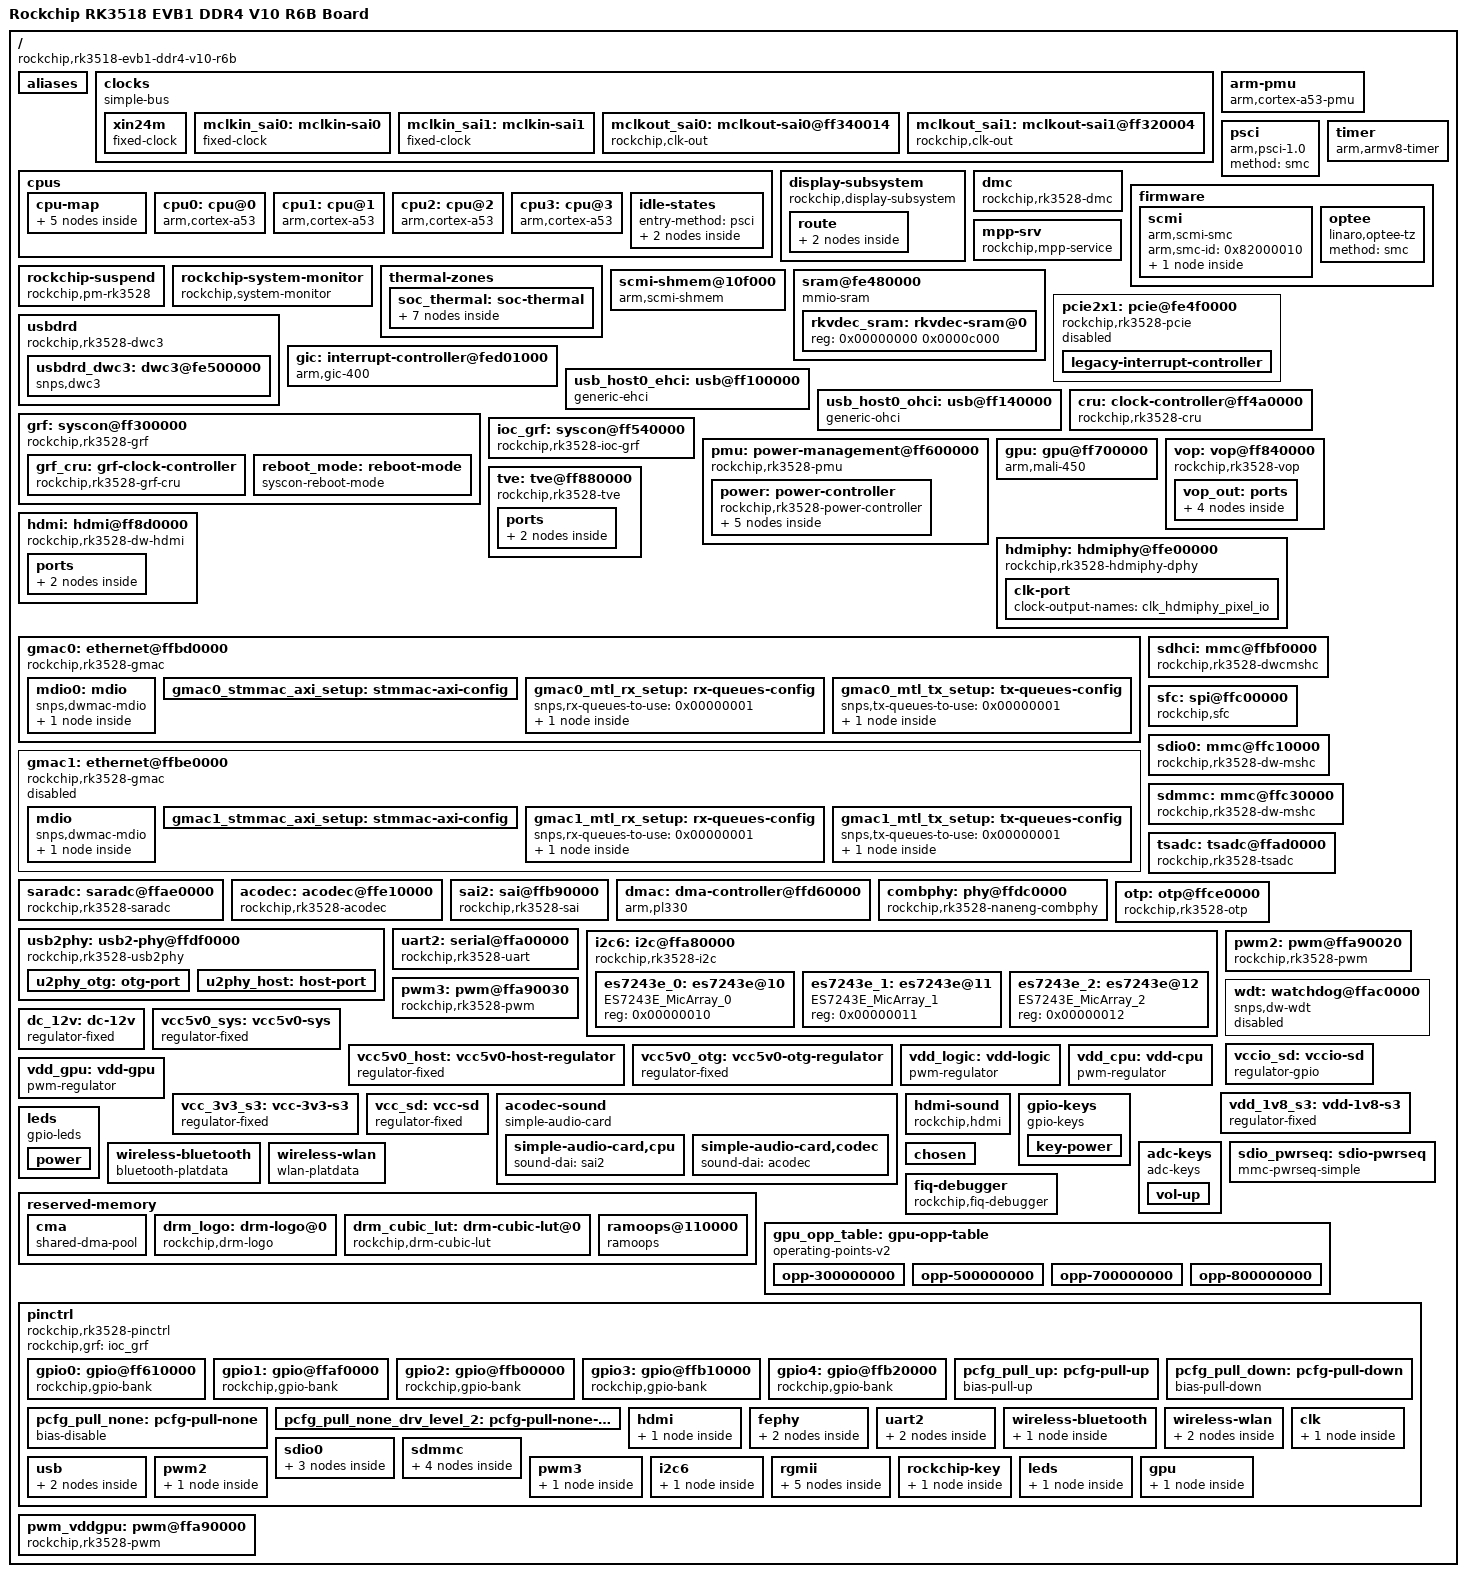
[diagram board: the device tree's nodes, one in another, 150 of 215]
/dts-v1/;

/ {
	compatible = "rockchip,rk3518-evb1-ddr4-v10-r6b", "rockchip,rk3528";
	model = "Rockchip RK3518 EVB1 DDR4 V10 R6B Board";
	interrupt-parent = <0x00000001>;
	#address-cells = <0x00000002>;
	#size-cells = <0x00000002>;

	aliases {
		ethernet0 = "/ethernet@ffbd0000";
		ethernet1 = "/ethernet@ffbe0000";
		gpio0 = "/pinctrl/gpio@ff610000";
		gpio1 = "/pinctrl/gpio@ffaf0000";
		gpio2 = "/pinctrl/gpio@ffb00000";
		gpio3 = "/pinctrl/gpio@ffb10000";
		gpio4 = "/pinctrl/gpio@ffb20000";
		i2c0 = "/i2c@ffa50000";
		i2c1 = "/i2c@ffa58000";
		i2c2 = "/i2c@ffa60000";
		i2c3 = "/i2c@ffa68000";
		i2c4 = "/i2c@ffa70000";
		i2c5 = "/i2c@ffa78000";
		i2c6 = "/i2c@ffa80000";
		i2c7 = "/i2c@ffa88000";
		serial0 = "/serial@ff9f0000";
		serial1 = "/serial@ff9f8000";
		serial2 = "/serial@ffa00000";
		serial3 = "/serial@ffa08000";
		serial4 = "/serial@ffa10000";
		serial5 = "/serial@ffa18000";
		serial6 = "/serial@ffa20000";
		serial7 = "/serial@ffa28000";
		spi0 = "/spi@ff9c0000";
		spi1 = "/spi@ff9d0000";
		spi2 = "/spi@ffc00000";
	};

	clocks {
		compatible = "simple-bus";
		#address-cells = <0x00000002>;
		#size-cells = <0x00000002>;
		ranges;

		xin24m: xin24m {
			compatible = "fixed-clock";
			#clock-cells = <0x00000000>;
			clock-frequency = <0x016e3600>;
			clock-output-names = "xin24m";
		};

		mclkin_sai0: mclkin-sai0 {
			compatible = "fixed-clock";
			#clock-cells = <0x00000000>;
			clock-frequency = <0x00000000>;
			clock-output-names = "i2s0_mclkin";
		};

		mclkin_sai1: mclkin-sai1 {
			compatible = "fixed-clock";
			#clock-cells = <0x00000000>;
			clock-frequency = <0x00000000>;
			clock-output-names = "i2s1_mclkin";
		};

		mclkout_sai0: mclkout-sai0@ff340014 {
			compatible = "rockchip,clk-out";
			reg = <0x00000000 0xff340014 0x00000000 0x00000004>;
			#clock-cells = <0x00000000>;
			clock-output-names = "mclk_sai0_to_io";
			rockchip,bit-shift = <0x00000001>;
			rockchip,bit-set-to-disable;
		};

		mclkout_sai1: mclkout-sai1@ff320004 {
			compatible = "rockchip,clk-out";
			reg = <0x00000000 0xff320004 0x00000000 0x00000004>;
			#clock-cells = <0x00000000>;
			clock-output-names = "mclk_sai1_to_io";
			rockchip,bit-shift = <0x0000000e>;
			rockchip,bit-set-to-disable;
		};
	};

	cpus {
		#address-cells = <0x00000002>;
		#size-cells = <0x00000000>;

		cpu-map {
			cluster0 {
				core0 { cpu = <&cpu0>; };
				core1 { cpu = <&cpu1>; };
				core2 { cpu = <&cpu2>; };
				core3 { cpu = <&cpu3>; };
			};
		};

		cpu0: cpu@0 {
			device_type = "cpu";
			compatible = "arm,cortex-a53";
			reg = <0x00000000 0x00000000>;
			enable-method = "psci";
			#cooling-cells = <0x00000002>;
			dynamic-power-coefficient = <0x00000093>;
			cpu-idle-states = <&CPU_SLEEP>;
		};

		cpu1: cpu@1 {
			device_type = "cpu";
			compatible = "arm,cortex-a53";
			reg = <0x00000000 0x00000001>;
			enable-method = "psci";
			cpu-idle-states = <&CPU_SLEEP>;
		};

		cpu2: cpu@2 {
			device_type = "cpu";
			compatible = "arm,cortex-a53";
			reg = <0x00000000 0x00000002>;
			enable-method = "psci";
			cpu-idle-states = <&CPU_SLEEP>;
		};

		cpu3: cpu@3 {
			device_type = "cpu";
			compatible = "arm,cortex-a53";
			reg = <0x00000000 0x00000003>;
			enable-method = "psci";
			cpu-idle-states = <&CPU_SLEEP>;
		};

		idle-states {
			entry-method = "psci";

			cpu-sleep0 {
				compatible = "arm,idle-state";
				local-timer-stop;
				arm,psci-suspend-param = <0x00010000>;
				entry-latency-us = <0x00000078>;
				exit-latency-us = <0x000000fa>;
				min-residency-us = <0x00000384>;
				status = "disabled";
			};

			CPU_SLEEP: cpu-sleep {
				compatible = "arm,idle-state";
				local-timer-stop;
				arm,psci-suspend-param = <0x00010000>;
				entry-latency-us = <0x00000078>;
				exit-latency-us = <0x000000fa>;
				min-residency-us = <0x00000384>;
				status = "okay";
			};
		};
	};

	arm-pmu {
		compatible = "arm,cortex-a53-pmu";
		interrupts = <0x00000000 0x000000ab 0x00000004
		              0x00000000 0x000000ac 0x00000004
		              0x00000000 0x000000ad 0x00000004
		              0x00000000 0x000000ae 0x00000004>;
		interrupt-affinity = <&cpu0>, <&cpu1>, <&cpu2>, <&cpu3>;
	};

	psci {
		compatible = "arm,psci-1.0";
		method = "smc";
	};

	timer {
		compatible = "arm,armv8-timer";
		interrupts = <0x00000001 0x0000000d 0x00000f08
		              0x00000001 0x0000000e 0x00000f08
		              0x00000001 0x0000000b 0x00000f08
		              0x00000001 0x0000000a 0x00000f08>;
	};

	display-subsystem {
		compatible = "rockchip,display-subsystem";
		ports = <&vop_out>;
		status = "okay";
		memory-region = <&drm_logo>, <&drm_cubic_lut>;
		memory-region-names = "drm-logo", "drm-cubic-lut";

		route {
			route-hdmi {
				status = "okay";
				logo,uboot = "logo.bmp";
				logo,kernel = "logo_kernel.bmp";
				logo,mode = "fullscreen";
				charge_logo,mode = "fullscreen";
				connect = <&vp0_out_hdmi>;
			};

			route-tve {
				status = "okay";
				logo,uboot = "logo.bmp";
				logo,kernel = "logo_kernel.bmp";
				logo,mode = "fullscreen";
				charge_logo,mode = "fullscreen";
				connect = <&vp1_out_tve>;
			};
		};
	};

	dmc: dmc {
		compatible = "rockchip,rk3528-dmc";
		interrupts = <0x00000000 0x00000011 0x00000004>;
		interrupt-names = "complete";
		devfreq = <&dmc>;
		clocks = <&scmi_clk 0x00000014>;
		clock-names = "dmc_clk";
		upthreshold = <0x00000028>;
		system-status-level = <0x00000001 0x00000008>;
		auto-min-freq = <0x0004f1a0>;
		auto-freq-en = <0x00000000>;
		status = "okay";
		center-supply = <&vdd_logic>;
	};

	firmware {
		scmi: scmi {
			compatible = "arm,scmi-smc";
			arm,smc-id = <0x82000010>;
			#address-cells = <0x00000001>;
			#size-cells = <0x00000000>;

			scmi_clk: protocol@14 {
				reg = <0x00000014>;
				#clock-cells = <0x00000001>;
				assigned-clocks = <&scmi_clk 0x00000015>;
				assigned-clock-rates = <0x47868c00>;
			};
		};

		optee {
			compatible = "linaro,optee-tz";
			method = "smc";
		};
	};

	mpp-srv {
		compatible = "rockchip,mpp-service";
		rockchip,taskqueue-count = <0x00000005>;
		rockchip,resetgroup-count = <0x00000005>;
		rockchip,iommu-shared-mask = <0x0000420a>;
		status = "okay";
	};

	rockchip-suspend {
		compatible = "rockchip,pm-rk3528";
		status = "okay";
		rockchip,sleep-debug-en = <0x00000001>;
		rockchip,sleep-mode-config = <0x00000001>;
		rockchip,wakeup-config = <0x00000011>;
		rockchip,pwm-regulator-config = <0x00000003>;
	};

	rockchip-system-monitor {
		compatible = "rockchip,system-monitor";
		rockchip,thermal-zone = "soc-thermal";
		rockchip,polling-delay = <0x000000c8>;
		rockchip,temp-hysteresis = <0x00001388>;
		rockchip,offline-cpu-temp = <0x00019a28>;
		rockchip,temp-offline-cpus = "2-3";
	};

	thermal-zones {
		soc_thermal: soc-thermal {
			polling-delay-passive = <0x00000014>;
			polling-delay = <0x000003e8>;
			sustainable-power = <0x0000027e>;
			thermal-sensors = <&tsadc 0x00000000>;

			trips {
				threshold: trip-point-0 {
					temperature = <0x00017318>;
					hysteresis = <0x000007d0>;
					type = "passive";
				};

				target: trip-point-1 {
					temperature = <0x0001adb0>;
					hysteresis = <0x000007d0>;
					type = "passive";
				};

				soc_crit: soc-crit {
					temperature = <0x0001d4c0>;
					hysteresis = <0x000007d0>;
					type = "critical";
				};
			};

			cooling-maps {
				map0 {
					trip = <&target>;
					cooling-device = <&cpu0 0xffffffff 0xffffffff>;
					contribution = <0x00000400>;
				};

				map1 {
					trip = <&target>;
					cooling-device = <&gpu 0xffffffff 0xffffffff>;
					contribution = <0x00000400>;
				};
			};
		};
	};

	scmi-shmem@10f000 {
		compatible = "arm,scmi-shmem";
		reg = <0x00000000 0x0010f000 0x00000000 0x00000100>;
	};

	sram@fe480000 {
		compatible = "mmio-sram";
		reg = <0x00000000 0xfe480000 0x00000000 0x0000c000>;
		#address-cells = <0x00000001>;
		#size-cells = <0x00000001>;
		ranges = <0x00000000 0x00000000 0xfe480000 0x0000c000>;

		rkvdec_sram: rkvdec-sram@0 {
			reg = <0x00000000 0x0000c000>;
		};
	};

	pcie2x1: pcie@fe4f0000 {
		compatible = "rockchip,rk3528-pcie", "snps,dw-pcie";
		#address-cells = <0x00000003>;
		#size-cells = <0x00000002>;
		bus-range = <0x00000000 0x000000ff>;
		device_type = "pci";
		max-link-speed = <0x00000002>;
		num-lanes = <0x00000001>;
		num-ib-windows = <0x00000008>;
		num-ob-windows = <0x00000008>;
		num-viewport = <0x00000004>;
		linux,pci-domain = <0x00000000>;
		reg = <0x00000000 0xfe4f0000 0x00000000 0x00010000
		       0x00000000 0xfe000000 0x00000000 0x00400000
		       0x00000000 0xfc000000 0x00000000 0x00100000>;
		reg-names = "pcie-apb", "pcie-dbi", "config";
		resets = <&cru 0x000001e3>, <&cru 0x000001e1>, <&cru 0x0000019b>;
		reset-names = "aclk", "pclk", "preset_cru";
		status = "disabled";

		legacy-interrupt-controller {
			interrupt-controller;
			#address-cells = <0x00000000>;
			#interrupt-cells = <0x00000001>;
			interrupts = <0x00000000 0x00000071 0x00000004>;
		};
	};

	usbdrd: usbdrd {
		compatible = "rockchip,rk3528-dwc3", "rockchip,rk3399-dwc3";
		clocks = <&cru 0x00000106>, <&cru 0x00000107>, <&cru 0x00000105>;
		clock-names = "ref_clk", "suspend_clk", "bus_clk";
		#address-cells = <0x00000002>;
		#size-cells = <0x00000002>;
		ranges;
		status = "okay";

		usbdrd_dwc3: dwc3@fe500000 {
			compatible = "snps,dwc3";
			reg = <0x00000000 0xfe500000 0x00000000 0x00400000>;
			interrupts = <0x00000000 0x00000098 0x00000004>;
			dr_mode = "host";
			phys = <&u2phy_otg>, <&combphy 0x00000004>;
			phy-names = "usb2-phy", "usb3-phy";
			phy_type = "utmi_wide";
			resets = <&cru 0x00000211>;
			reset-names = "usb3-otg";
			snps,dis_enblslpm_quirk;
			snps,dis-u1-entry-quirk;
			snps,dis-u2-entry-quirk;
			snps,dis-u2-freeclk-exists-quirk;
			snps,dis-del-phy-power-chg-quirk;
			snps,dis-tx-ipgap-linecheck-quirk;
			snps,dis_rxdet_inp3_quirk;
			snps,parkmode-disable-hs-quirk;
			snps,parkmode-disable-ss-quirk;
			quirk-skip-phy-init;
			status = "okay";
		};
	};

	gic: interrupt-controller@fed01000 {
		compatible = "arm,gic-400";
		#interrupt-cells = <0x00000003>;
		#address-cells = <0x00000000>;
		interrupt-controller;
		reg = <0x00000000 0xfed01000 0x00000000 0x00001000
		       0x00000000 0xfed02000 0x00000000 0x00002000
		       0x00000000 0xfed04000 0x00000000 0x00002000
		       0x00000000 0xfed06000 0x00000000 0x00002000>;
		interrupts = <0x00000001 0x00000009 0x00000f08>;
	};

	usb_host0_ehci: usb@ff100000 {
		compatible = "generic-ehci";
		reg = <0x00000000 0xff100000 0x00000000 0x00040000>;
		interrupts = <0x00000000 0x0000008f 0x00000004>;
		clocks = <&cru 0x000001a0>, <&cru 0x000001a1>, <&u2phy_host>;
		clock-names = "usbhost", "arbiter", "utmi";
		phys = <&u2phy_host>;
		phy-names = "usb2-phy";
		status = "okay";
	};

	usb_host0_ohci: usb@ff140000 {
		compatible = "generic-ohci";
		reg = <0x00000000 0xff140000 0x00000000 0x00040000>;
		interrupts = <0x00000000 0x00000090 0x00000004>;
		clocks = <&cru 0x000001a0>, <&cru 0x000001a1>, <&u2phy_host>;
		clock-names = "usbhost", "arbiter", "utmi";
		phys = <&u2phy_host>;
		phy-names = "usb2-phy";
		status = "okay";
	};

	grf: syscon@ff300000 {
		compatible = "rockchip,rk3528-grf", "syscon", "simple-mfd";
		reg = <0x00000000 0xff300000 0x00000000 0x00090000>;

		grf_cru: grf-clock-controller {
			compatible = "rockchip,rk3528-grf-cru";
			#clock-cells = <0x00000001>;
		};

		reboot_mode: reboot-mode {
			compatible = "syscon-reboot-mode";
			offset = <0x00000200>;
			mode-bootloader = <0x5242c309>;
			mode-charge = <0x5242c30b>;
			mode-fastboot = <0x5242c303>;
			mode-normal = <0x5242c301>;
			mode-recovery = <0x5242c30f>;
			mode-ums = <0x5242c30c>;
			mode-panic = <0x5242c307>;
			mode-watchdog = <0x5242c308>;
		};
	};

	cru: clock-controller@ff4a0000 {
		compatible = "rockchip,rk3528-cru";
		reg = <0x00000000 0xff4a0000 0x00000000 0x00030000>;
		rockchip,grf = <&grf>;
		#clock-cells = <0x00000001>;
		#reset-cells = <0x00000001>;
		assigned-clocks = <&scmi_clk 0x00000015>;
		assigned-clock-rates = <0x47868c00>;
	};

	ioc_grf: syscon@ff540000 {
		compatible = "rockchip,rk3528-ioc-grf", "syscon";
		reg = <0x00000000 0xff540000 0x00000000 0x00040000>;
	};

	pmu: power-management@ff600000 {
		compatible = "rockchip,rk3528-pmu", "simple-mfd";
		reg = <0x00000000 0xff600000 0x00000000 0x00002000>;

		power: power-controller {
			compatible = "rockchip,rk3528-power-controller";
			#power-domain-cells = <0x00000001>;
			#address-cells = <0x00000001>;
			#size-cells = <0x00000000>;
			status = "okay";

			pd_gpu: pd_gpu@4 {
				reg = <0x00000004>;
			};

			pd_rkvdec: pd_rkvdec@5 {
				reg = <0x00000005>;
			};

			pd_rkvenc: pd_rkvenc@6 {
				reg = <0x00000006>;
			};

			pd_vo: pd_vo@7 {
				reg = <0x00000007>;
			};

			pd_vpu: pd_vpu@8 {
				reg = <0x00000008>;
			};
		};
	};

	gpu: gpu@ff700000 {
		compatible = "arm,mali-450";
		reg = <0x00000000 0xff700000 0x00000000 0x00040000>;
		clocks = <&scmi_clk 0x00000016>, <&cru 0x00000113>, <&cru 0x0000010e>;
		clock-names = "clk_mali", "aclk_gpu_mali", "pclk_gpu";
		assigned-clocks = <&scmi_clk 0x00000016>;
		assigned-clock-rates = <0x11e1a300>;
		power-domains = <&power 0x00000004>;
		operating-points-v2 = <&gpu_opp_table>;
		#cooling-cells = <0x00000002>;
		rockchip,grf = <&grf>;
		status = "okay";
		mali-supply = <&vdd_gpu>;
	};

	vop: vop@ff840000 {
		compatible = "rockchip,rk3528-vop";
		reg = <0x00000000 0xff840000 0x00000000 0x00003000
		       0x00000000 0xff845000 0x00000000 0x00001000
		       0x00000000 0xff846400 0x00000000 0x00000800>;
		reg-names = "regs", "gamma_lut", "acm_regs";
		interrupts = <0x00000000 0x0000006d 0x00000004>;
		clocks = <&cru 0x00000157>, <&cru 0x00000154>,
		         <&cru 0x00000155>, <&cru 0x00000156>;
		clock-names = "aclk_vop", "hclk_vop", "dclk_vp0", "dclk_vp1";
		assigned-clocks = <&cru 0x00000155>;
		rockchip,grf = <&grf>;
		status = "okay";

		vop_out: ports {
			#address-cells = <0x00000001>;

			port@0 {
				reg = <0x00000000>;
				#address-cells = <0x00000001>;
				#size-cells = <0x00000000>;

				vp0_out_hdmi: endpoint@0 {
					reg = <0x00000000>;
					remote-endpoint = <&hdmi_in_vp0>;
				};
			};

			port@1 {
				reg = <0x00000001>;
				#address-cells = <0x00000001>;
				#size-cells = <0x00000000>;

				vp1_out_tve: endpoint@0 {
					reg = <0x00000000>;
					remote-endpoint = <&tve_in_vp1>;
				};
			};
		};
	};

	tve: tve@ff880000 {
		compatible = "rockchip,rk3528-tve";
		reg = <0x00000000 0xff880000 0x00000000 0x00004000
		       0x00000000 0xffe00000 0x00000000 0x00000300>;
		interrupts = <0x00000000 0x00000068 0x00000004>;
		clocks = <&cru 0x00000166>, <&cru 0x0000018f>,
		         <&cru 0x00000167>, <&cru 0x00000168>;
		clock-names = "hclk", "pclk_vdac", "dclk", "dclk_4x";
		rockchip,grf = <&grf>;
		status = "okay";

		ports {
			#address-cells = <0x00000001>;
			#size-cells = <0x00000000>;

			port@0 {
				reg = <0x00000000>;
				#address-cells = <0x00000001>;
				#size-cells = <0x00000000>;

				tve_in_vp1: endpoint@0 {
					reg = <0x00000000>;
					remote-endpoint = <&vp1_out_tve>;
					status = "okay";
				};
			};
		};
	};

	hdmi: hdmi@ff8d0000 {
		compatible = "rockchip,rk3528-dw-hdmi";
		reg = <0x00000000 0xff8d0000 0x00000000 0x00020000
		       0x00000000 0xff610000 0x00000000 0x00000200>;
		interrupts = <0x00000000 0x00000066 0x00000004
		              0x00000000 0x00000067 0x00000004>;
		interrupt-names = "hdmi", "hdmi_wakeup";
		clocks = <&cru 0x00000158>, <&cru 0x00000159>,
		         <&cru 0x0000015a>, <&cru 0x00000155>;
		clock-names = "iahb", "isfr", "cec", "dclk_vp0";
		ddc-i2c-scl-high-time-ns = <0x00002599>;
		ddc-i2c-scl-low-time-ns = <0x00002710>;
		reg-io-width = <0x00000004>;
		rockchip,grf = <&grf>;
		rockchip,cts-manual;
		pinctrl-names = "default";
		pinctrl-0 = <&hdmi_pins>;
		phys = <&hdmiphy>;
		phy-names = "hdmi";
		#sound-dai-cells = <0x00000000>;
		hpd-gpios = <&gpio0 0x00000002 0x00000000>;
		status = "okay";

		ports {
			#address-cells = <0x00000001>;
			#size-cells = <0x00000000>;

			port@0 {
				reg = <0x00000000>;
				#address-cells = <0x00000001>;
				#size-cells = <0x00000000>;

				hdmi_in_vp0: endpoint@0 {
					reg = <0x00000000>;
					remote-endpoint = <&vp0_out_hdmi>;
					status = "okay";
				};
			};
		};
	};

	hdmiphy: hdmiphy@ffe00000 {
		compatible = "rockchip,rk3528-hdmiphy-dphy";
		reg = <0x00000000 0xffe00000 0x00000000 0x00010000>;
		interrupts = <0x00000000 0x00000065 0x00000004>;
		#phy-cells = <0x00000000>;
		clocks = <&cru 0x00000160>, <&xin24m>;
		clock-names = "sysclk", "refclk";
		status = "okay";

		clk-port {
			#clock-cells = <0x00000000>;
			clock-output-names = "clk_hdmiphy_pixel_io";
			status = "okay";
		};
	};

	gmac0: ethernet@ffbd0000 {
		compatible = "rockchip,rk3528-gmac", "snps,dwmac-4.20a";
		reg = <0x00000000 0xffbd0000 0x00000000 0x00010000>;
		interrupts = <0x00000000 0x00000071 0x00000004
		              0x00000000 0x00000074 0x00000004>;
		interrupt-names = "macirq", "eth_wake_irq";
		rockchip,grf = <&grf>;
		clocks = <&cru 0x0000017b>, <&cru 0x0000017e>, <&cru 0x0000017d>,
		         <&cru 0x0000017a>, <&cru 0x00000179>;
		clock-names = "stmmaceth", "clk_mac_ref", "mac_clk_rx",
		              "mac_clk_tx", "pclk_mac", "aclk_mac";
		resets = <&cru 0x0000029a>;
		reset-names = "stmmaceth";
		snps,mixed-burst;
		snps,axi-config = <&gmac0_stmmac_axi_setup>;
		snps,mtl-rx-config = <&gmac0_mtl_rx_setup>;
		snps,mtl-tx-config = <&gmac0_mtl_tx_setup>;
		phy-mode = "rmii";
		clock_in_out = "input";
		phy-handle = <&rmii0_phy>;
		status = "okay";

		mdio0: mdio {
			compatible = "snps,dwmac-mdio";
			#address-cells = <0x00000001>;
			#size-cells = <0x00000000>;

			rmii0_phy: ethernet-phy@2 {
				compatible = "ethernet-phy-id0044.1400", "ethernet-phy-ieee802.3-c22";
				reg = <0x00000002>;
				clocks = <&cru 0x0000018e>;
				resets = <&cru 0x000002a3>;
				phy-is-integrated;
				pinctrl-names = "default";
				pinctrl-0 = <&fephym0_led_link>, <&fephym0_led_spd>;
				rockchip,thermal-zone = "soc-thermal";
			};
		};

		gmac0_stmmac_axi_setup: stmmac-axi-config {
			snps,wr_osr_lmt = <0x00000004>;
			snps,rd_osr_lmt = <0x00000008>;
			snps,blen = <0x00000000 0x00000000 0x00000000 0x00000000
			             0x00000010 0x00000008 0x00000004>;
		};

		gmac0_mtl_rx_setup: rx-queues-config {
			snps,rx-queues-to-use = <0x00000001>;
			queue0 {};
		};

		gmac0_mtl_tx_setup: tx-queues-config {
			snps,tx-queues-to-use = <0x00000001>;
			queue0 {};
		};
	};

	gmac1: ethernet@ffbe0000 {
		compatible = "rockchip,rk3528-gmac", "snps,dwmac-4.20a";
		reg = <0x00000000 0xffbe0000 0x00000000 0x00010000>;
		interrupts = <0x00000000 0x00000079 0x00000004
		              0x00000000 0x0000007c 0x00000004>;
		interrupt-names = "macirq", "eth_wake_irq";
		rockchip,grf = <&grf>;
		clocks = <&cru 0x000000d2>, <&cru 0x000000cf>, <&cru 0x000000ce>;
		clock-names = "stmmaceth", "clk_mac_ref", "pclk_mac", "aclk_mac";
		resets = <&cru 0x000001c5>;
		reset-names = "stmmaceth";
		snps,mixed-burst;
		snps,axi-config = <&gmac1_stmmac_axi_setup>;
		snps,mtl-rx-config = <&gmac1_mtl_rx_setup>;
		snps,mtl-tx-config = <&gmac1_mtl_tx_setup>;
		status = "disabled";
		phy-mode = "rgmii-rxid";
		assigned-clock-rates = <0x00000000 0x07735940>;
		pinctrl-names = "default";
		pinctrl-0 = <&rgmii_miim>, <&rgmii_tx_bus2>, <&rgmii_rx_bus2>,
		             <&rgmii_rgmii_clk>, <&rgmii_bus>;
		phy-handle = <&rgmii_phy>;

		mdio: mdio {
			compatible = "snps,dwmac-mdio";
			#address-cells = <0x00000001>;
			#size-cells = <0x00000000>;

			rgmii_phy: phy@1 {
				compatible = "ethernet-phy-ieee802.3-c22";
				reg = <0x00000001>;
				clocks = <&cru 0x00000094>;
			};
		};

		gmac1_stmmac_axi_setup: stmmac-axi-config {
			snps,wr_osr_lmt = <0x00000004>;
			snps,rd_osr_lmt = <0x00000008>;
			snps,blen = <0x00000000 0x00000000 0x00000000 0x00000000
			             0x00000010 0x00000008 0x00000004>;
		};

		gmac1_mtl_rx_setup: rx-queues-config {
			snps,rx-queues-to-use = <0x00000001>;
			queue0 {};
		};

		gmac1_mtl_tx_setup: tx-queues-config {
			snps,tx-queues-to-use = <0x00000001>;
			queue0 {};
		};
	};

	sdhci: mmc@ffbf0000 {
		compatible = "rockchip,rk3528-dwcmshc";
		reg = <0x00000000 0xffbf0000 0x00000000 0x00010000>;
		interrupts = <0x00000000 0x00000088 0x00000004>;
		assigned-clocks = <&cru 0x000000a6>, <&cru 0x000000a0>, <&cru 0x000000a3>;
		assigned-clock-rates = <0x0bebc200 0x016e3600 0x016e3600>;
		clocks = <&cru 0x000000a3>, <&cru 0x000000a4>, <&cru 0x000000a5>,
		         <&cru 0x000000a6>, <&cru 0x000000a7>;
		clock-names = "core", "bus", "axi", "block", "timer";
		resets = <&cru 0x0000019f>, <&cru 0x000001a0>, <&cru 0x000001a1>,
		         <&cru 0x000001a2>, <&cru 0x000001a3>;
		reset-names = "core", "bus", "axi", "block", "timer";
		max-frequency = <0x0bebc200>;
		status = "okay";
		bus-width = <0x00000008>;
		no-sd;
		no-sdio;
		non-removable;
		mmc-hs200-enhanced-strobe;
	};

	sfc: spi@ffc00000 {
		compatible = "rockchip,sfc";
		reg = <0x00000000 0xffc00000 0x00000000 0x00004000>;
		interrupts = <0x00000000 0x00000087 0x00000004>;
		clocks = <&cru 0x000000a1>, <&cru 0x000000a0>;
		clock-names = "clk_sfc", "hclk_sfc";
		assigned-clocks = <&cru 0x000000a1>;
		#address-cells = <0x00000001>;
		#size-cells = <0x00000000>;
		status = "okay";
	};

	sdio0: mmc@ffc10000 {
		compatible = "rockchip,rk3528-dw-mshc", "rockchip,rk3288-dw-mshc";
		reg = <0x00000000 0xffc10000 0x00000000 0x00004000>;
		interrupts = <0x00000000 0x00000089 0x00000004>;
		max-frequency = <0x05f5e100>;
		clocks = <&cru 0x000000f1>, <&cru 0x000000f0>,
		         <&cru 0x00000085 3>, <&cru 0x00000085 4>;
		clock-names = "biu", "ciu", "ciu-drive", "ciu-sample";
		fifo-depth = <0x00000100>;
		resets = <&cru 0x00000202>;
		reset-names = "reset";
		status = "okay";
		no-sd;
		no-mmc;
		supports-sdio;
		bus-width = <0x00000004>;
		disable-wp;
		cap-sd-highspeed;
		cap-sdio-irq;
		keep-power-in-suspend;
		non-removable;
		pinctrl-names = "default";
		pinctrl-0 = <&sdio0_bus4>, <&sdio0_clk>, <&sdio0_cmd>;
		sd-uhs-sdr104;
		mmc-pwrseq = <&sdio_pwrseq>;
	};

	sdmmc: mmc@ffc30000 {
		compatible = "rockchip,rk3528-dw-mshc", "rockchip,rk3288-dw-mshc";
		reg = <0x00000000 0xffc30000 0x00000000 0x00004000>;
		interrupts = <0x00000000 0x0000008b 0x00000004>;
		max-frequency = <0x08f0d180>;
		clocks = <&cru 0x00000198>, <&cru 0x00000197>,
		         <&cru 0x00000085 1>, <&cru 0x00000085 2>;
		clock-names = "biu", "ciu", "ciu-drive", "ciu-sample";
		fifo-depth = <0x00000100>;
		resets = <&cru 0x000002a9>;
		reset-names = "reset";
		rockchip,use-v-cycle;
		status = "okay";
		bus-width = <0x00000004>;
		cap-mmc-highspeed;
		cap-sd-highspeed;
		disable-wp;
		pinctrl-names = "default";
		pinctrl-0 = <&sdmmc_bus4>, <&sdmmc_clk>, <&sdmmc_cmd>, <&sdmmc_det>;
		rockchip,default-sample-phase = <0x0000005a>;
		supports-sd;
		sd-uhs-sdr12;
		sd-uhs-sdr25;
		sd-uhs-sdr50;
		sd-uhs-sdr104;
		vqmmc-supply = <&vccio_sd>;
		vmmc-supply = <&vcc_sd>;
	};

	tsadc: tsadc@ffad0000 {
		compatible = "rockchip,rk3528-tsadc";
		reg = <0x00000000 0xffad0000 0x00000000 0x00000400>;
		rockchip,grf = <&grf>;
		interrupts = <0x00000000 0x00000057 0x00000004>;
		clocks = <&cru 0x00000103>, <&cru 0x00000104>, <&cru 0x00000102>;
		clock-names = "tsadc_tsen", "tsadc", "apb_pclk";
		assigned-clocks = <&cru 0x00000103>, <&cru 0x00000104>;
		assigned-clock-rates = <0x00124f80 0x00b71b00>;
		resets = <&cru 0x0000020f>, <&cru 0x00000210>;
		reset-names = "tsadc", "tsadc-apb";
		#thermal-sensor-cells = <0x00000001>;
		rockchip,hw-tshut-temp = <0x0001d4c0>;
		rockchip,hw-tshut-mode = <0x00000000>;
		rockchip,hw-tshut-polarity = <0x00000000>;
		status = "okay";
	};

	saradc: saradc@ffae0000 {
		compatible = "rockchip,rk3528-saradc";
		reg = <0x00000000 0xffae0000 0x00000000 0x00010000>;
		interrupts = <0x00000000 0x0000008c 0x00000004>;
		#io-channel-cells = <0x00000001>;
		clocks = <&cru 0x00000101>, <&cru 0x00000100>;
		clock-names = "saradc", "apb_pclk";
		resets = <&cru 0x0000020b>;
		reset-names = "saradc-apb";
		status = "okay";
		vref-supply = <&vdd_1v8_s3>;
	};

	acodec: acodec@ffe10000 {
		compatible = "rockchip,rk3528-acodec";
		reg = <0x00000000 0xffe10000 0x00000000 0x00001000>;
		#sound-dai-cells = <0x00000000>;
		clocks = <&cru 0x000000b2>, <&cru 0x000000b3>;
		clock-names = "pclk", "mclk";
		resets = <&cru 0x000001ad>;
		reset-names = "acodec";
		status = "okay";
		pa-ctl-gpios = <&gpio0 0x00000008 0x00000000>;
	};

	sai2: sai@ffb90000 {
		compatible = "rockchip,rk3528-sai", "rockchip,sai-v1";
		reg = <0x00000000 0xffb90000 0x00000000 0x00001000>;
		interrupts = <0x00000000 0x0000007f 0x00000004>;
		clocks = <&cru 0x000000b1>, <&cru 0x000000b0>;
		clock-names = "mclk", "hclk";
		dmas = <&dmac 0x00000004>;
		dma-names = "tx";
		resets = <&cru 0x000001ac>, <&cru 0x000001ab>;
		reset-names = "m", "h";
		#sound-dai-cells = <0x00000000>;
		status = "okay";
	};

	dmac: dma-controller@ffd60000 {
		compatible = "arm,pl330", "arm,primecell";
		reg = <0x00000000 0xffd60000 0x00000000 0x00004000>;
		clocks = <&cru 0x00000068>;
		clock-names = "apb_pclk";
		#dma-cells = <0x00000001>;
		arm,pl330-periph-burst;
	};

	combphy: phy@ffdc0000 {
		compatible = "rockchip,rk3528-naneng-combphy";
		reg = <0x00000000 0xffdc0000 0x00000000 0x00010000>;
		#phy-cells = <0x00000001>;
		clocks = <&cru 0x00000091>, <&cru 0x000000dc>, <&cru 0x000000dd>;
		clock-names = "refclk", "apbclk", "pipe_clk";
		assigned-clocks = <&cru 0x00000091>;
		assigned-clock-rates = <0x05f5e100>;
		resets = <&cru 0x000001e6>, <&cru 0x000001e2>;
		reset-names = "combphy-apb", "combphy";
		rockchip,pipe-grf = <&grf>;
		rockchip,pipe-phy-grf = <&ioc_grf>;
		status = "okay";
	};

	usb2phy: usb2-phy@ffdf0000 {
		compatible = "rockchip,rk3528-usb2phy";
		reg = <0x00000000 0xffdf0000 0x00000000 0x00010000>;
		clocks = <&cru 0x000001ab>, <&cru 0x000001aa>;
		clock-names = "phyclk", "apb_clk";
		#clock-cells = <0x00000000>;
		rockchip,usbgrf = <&grf>;
		status = "okay";

		u2phy_otg: otg-port {
			#phy-cells = <0x00000000>;
			interrupts = <0x00000000 0x00000092 0x00000004
			              0x00000000 0x00000093 0x00000004
			              0x00000000 0x00000094 0x00000004>;
			interrupt-names = "otg-bvalid", "otg-id", "linestate";
			status = "okay";
			vbus-supply = <&vcc5v0_otg>;
		};

		u2phy_host: host-port {
			#phy-cells = <0x00000000>;
			interrupts = <0x00000000 0x00000096 0x00000004>;
			interrupt-names = "linestate";
			status = "okay";
			phy-supply = <&vcc5v0_host>;
		};
	};

	otp: otp@ffce0000 {
		compatible = "rockchip,rk3528-otp";
		reg = <0x00000000 0xffce0000 0x00000000 0x00004000>;
		#address-cells = <0x00000001>;
		#size-cells = <0x00000001>;
		clocks = <&cru 0x0000019d>, <&cru 0x0000019c>, <&cru 0x0000019b>;
		clock-names = "usr", "sbpi", "apb";
		resets = <&cru 0x000002ad>, <&cru 0x000002ac>, <&cru 0x000002ab>;
		reset-names = "usr", "sbpi", "apb";
	};

	uart2: serial@ffa00000 {
		compatible = "rockchip,rk3528-uart", "snps,dw-apb-uart";
		reg = <0x00000000 0xffa00000 0x00000000 0x00000100>;
		interrupts = <0x00000000 0x0000002a 0x00000004>;
		clocks = <&cru 0x0000001b>, <&cru 0x000000c0>;
		clock-names = "baudclk", "apb_pclk";
		reg-shift = <0x00000002>;
		reg-io-width = <0x00000004>;
		dmas = <&dmac 0x0000000d>, <&dmac 0x0000000c>;
		pinctrl-names = "default";
		pinctrl-0 = <&uart2m1_xfer>;
		status = "okay";
	};

	i2c6: i2c@ffa80000 {
		compatible = "rockchip,rk3528-i2c", "rockchip,rk3399-i2c";
		reg = <0x00000000 0xffa80000 0x00000000 0x00001000>;
		clocks = <&cru 0x000000cd>, <&cru 0x000000cc>;
		clock-names = "i2c", "pclk";
		interrupts = <0x00000000 0x00000043 0x00000004>;
		pinctrl-names = "default";
		pinctrl-0 = <&i2c6m0_xfer>;
		#address-cells = <0x00000001>;
		#size-cells = <0x00000000>;
		status = "okay";

		es7243e_0: es7243e@10 {
			status = "okay";
			#sound-dai-cells = <0x00000000>;
			compatible = "ES7243E_MicArray_0";
			reg = <0x00000010>;
		};

		es7243e_1: es7243e@11 {
			status = "okay";
			#sound-dai-cells = <0x00000000>;
			compatible = "ES7243E_MicArray_1";
			reg = <0x00000011>;
		};

		es7243e_2: es7243e@12 {
			status = "okay";
			#sound-dai-cells = <0x00000000>;
			compatible = "ES7243E_MicArray_2";
			reg = <0x00000012>;
		};
	};

	pwm2: pwm@ffa90020 {
		compatible = "rockchip,rk3528-pwm", "rockchip,rk3328-pwm";
		reg = <0x00000000 0xffa90020 0x00000000 0x00000010>;
		interrupts = <0x00000000 0x00000035 0x00000004>;
		#pwm-cells = <0x00000003>;
		pinctrl-names = "active";
		pinctrl-0 = <&pwm2m0_pins>;
		clocks = <&cru 0x0000007f>, <&cru 0x0000007e>;
		clock-names = "pwm", "pclk";
		status = "okay";
	};

	pwm3: pwm@ffa90030 {
		compatible = "rockchip,rk3528-pwm", "rockchip,rk3328-pwm";
		reg = <0x00000000 0xffa90030 0x00000000 0x00000010>;
		interrupts = <0x00000000 0x00000036 0x00000004>;
		#pwm-cells = <0x00000003>;
		pinctrl-names = "default";
		pinctrl-0 = <&pwm3m0_pins>;
		clocks = <&cru 0x0000007f>, <&cru 0x0000007e>;
		clock-names = "pwm", "pclk";
		status = "okay";
		/* IR receiver */
		remote_pwm_id = <0x00000007>;
		remote_support_psci = <0x00000000>;
	};

	wdt: watchdog@ffac0000 {
		compatible = "snps,dw-wdt";
		reg = <0x00000000 0xffac0000 0x00000000 0x00000100>;
		clocks = <&cru 0x00000073>, <&cru 0x00000072>;
		clock-names = "tclk", "pclk";
		interrupts = <0x00000000 0x0000001c 0x00000004>;
		status = "disabled";
	};

	/* ==================== Regulators ==================== */

	dc_12v: dc-12v {
		compatible = "regulator-fixed";
		regulator-name = "dc_12v";
		regulator-always-on;
		regulator-boot-on;
		regulator-min-microvolt = <0x00b71b00>;
		regulator-max-microvolt = <0x00b71b00>;
	};

	vcc5v0_sys: vcc5v0-sys {
		compatible = "regulator-fixed";
		regulator-name = "vcc5v0_sys";
		regulator-always-on;
		regulator-boot-on;
		regulator-min-microvolt = <0x004c4b40>;
		regulator-max-microvolt = <0x004c4b40>;
		vin-supply = <&dc_12v>;
	};

	vcc5v0_host: vcc5v0-host-regulator {
		compatible = "regulator-fixed";
		regulator-name = "vcc5v0_host";
		regulator-boot-on;
		regulator-always-on;
		regulator-min-microvolt = <0x004c4b40>;
		regulator-max-microvolt = <0x004c4b40>;
		enable-active-high;
		gpio = <&gpio4 0x0000000d 0x00000000>;
		vin-supply = <&vcc5v0_sys>;
		pinctrl-names = "default";
		pinctrl-0 = <&vcc5v0_host_en>;
	};

	vcc5v0_otg: vcc5v0-otg-regulator {
		compatible = "regulator-fixed";
		regulator-name = "vcc5v0_otg";
		regulator-min-microvolt = <0x004c4b40>;
		regulator-max-microvolt = <0x004c4b40>;
		enable-active-high;
		gpio = <&gpio4 0x00000011 0x00000000>;
		vin-supply = <&vcc5v0_sys>;
		pinctrl-names = "default";
		pinctrl-0 = <&vcc5v0_otg_en>;
	};

	vccio_sd: vccio-sd {
		compatible = "regulator-gpio";
		regulator-name = "vccio_sd";
		regulator-min-microvolt = <0x001b7740>;
		regulator-max-microvolt = <0x00325aa0>;
		gpios = <&gpio4 0x0000000e 0x00000000>;
		vin-supply = <&vcc5v0_sys>;
		states = <0x001b7740 0x00000000 0x00325aa0 0x00000001>;
	};

	vdd_logic: vdd-logic {
		compatible = "pwm-regulator";
		pwms = <&pwm2 0x00000000 0x00001388 0x00000001>;
		regulator-name = "vdd_logic";
		regulator-min-microvolt = <0x000ac1e8>;
		regulator-max-microvolt = <0x00118460>;
		regulator-init-microvolt = <0x000dbba0>;
		regulator-always-on;
		regulator-boot-on;
		regulator-settling-time-up-us = <0x000000fa>;
		pwm-supply = <&vcc5v0_sys>;
		status = "okay";
	};

	vdd_cpu: vdd-cpu {
		compatible = "pwm-regulator";
		pwms = <&pwm3 0x00000000 0x00001388 0x00000001>;
		regulator-name = "vdd_cpu";
		regulator-min-microvolt = <0x000ac1e8>;
		regulator-max-microvolt = <0x00125368>;
		regulator-init-microvolt = <0x000e8aa8>;
		regulator-always-on;
		regulator-boot-on;
		regulator-settling-time-up-us = <0x000000fa>;
		pwm-supply = <&vcc5v0_sys>;
		status = "okay";
	};

	vdd_gpu: vdd-gpu {
		compatible = "pwm-regulator";
		pwms = <&pwm_vddgpu 0x00000000 0x00001388 0x00000001>;
		regulator-name = "vdd_gpu";
		regulator-min-microvolt = <0x000ac1e8>;
		regulator-max-microvolt = <0x00118460>;
		regulator-init-microvolt = <0x000dbba0>;
		regulator-always-on;
		regulator-boot-on;
		regulator-settling-time-up-us = <0x000000fa>;
		pwm-supply = <&vcc5v0_sys>;
		status = "okay";
	};

	vdd_1v8_s3: vdd-1v8-s3 {
		compatible = "regulator-fixed";
		regulator-name = "vdd_1v8_s3";
		regulator-always-on;
		regulator-boot-on;
		regulator-min-microvolt = <0x001b7740>;
		regulator-max-microvolt = <0x001b7740>;
		vin-supply = <&vcc5v0_sys>;
	};

	vcc_3v3_s3: vcc-3v3-s3 {
		compatible = "regulator-fixed";
		regulator-name = "vcc_3v3_s3";
		regulator-always-on;
		regulator-boot-on;
		regulator-min-microvolt = <0x00325aa0>;
		regulator-max-microvolt = <0x00325aa0>;
		vin-supply = <&vcc5v0_sys>;
	};

	vcc_sd: vcc-sd {
		compatible = "regulator-fixed";
		regulator-name = "vcc_sd";
		regulator-min-microvolt = <0x00325aa0>;
		regulator-max-microvolt = <0x00325aa0>;
		vin-supply = <&vcc_3v3_s3>;
	};

	/* ==================== Sound ==================== */

	acodec-sound {
		status = "okay";
		compatible = "simple-audio-card";
		simple-audio-card,name = "rockchip,acodec";
		simple-audio-card,format = "i2s";
		simple-audio-card,mclk-fs = <0x00000100>;

		simple-audio-card,cpu {
			sound-dai = <&sai2>;
		};

		simple-audio-card,codec {
			sound-dai = <&acodec>;
		};
	};

	hdmi-sound {
		compatible = "rockchip,hdmi";
		rockchip,mclk-fs = <0x00000080>;
		rockchip,card-name = "rockchip,hdmi";
		rockchip,cpu = <&sai2>;
		rockchip,codec = <&hdmi>;
	};

	/* ==================== GPIO / Keys / LEDs ==================== */

	gpio-keys {
		compatible = "gpio-keys";
		autorepeat;
		pinctrl-names = "default";
		pinctrl-0 = <&power_key>;

		key-power {
			gpios = <&gpio1 0x00000012 0x00000001>;
			linux,code = <0x00000074>;
			label = "GPIO Key Power";
			debounce-interval = <0x00000064>;
		};
	};

	leds {
		compatible = "gpio-leds";

		power {
			label = "power";
			gpios = <&gpio4 0x0000000b 0x00000000>;
			linux,default-trigger = "default-on";
			default-state = "on";
		};
	};

	adc-keys {
		status = "okay";
		compatible = "adc-keys";
		io-channels = <&saradc 0x00000001>;
		io-channel-names = "buttons";
		poll-interval = <0x00000064>;
		keyup-threshold-microvolt = <0x001b7740>;

		vol-up {
			label = "volume up";
			linux,code = <0x000000c2>;
			press-threshold-microvolt = <0x000006d6>;
		};
	};

	/* ==================== WiFi / BT ==================== */

	sdio_pwrseq: sdio-pwrseq {
		compatible = "mmc-pwrseq-simple";
		pinctrl-names = "default";
		pinctrl-0 = <&wifi_enable_h>, <&wifi_32k>;
		post-power-on-delay-ms = <0x000000c8>;
		reset-gpios = <&gpio1 0x00000006 0x00000001>;
		status = "okay";
	};

	wireless-bluetooth {
		compatible = "bluetooth-platdata";
		uart_rts_gpios = <&gpio1 0x0000000a 0x00000001>;
		pinctrl-names = "default", "rts_gpio";
		pinctrl-0 = <&uart2m1_gpios>, <&bt_wake_gpio>;
		pinctrl-1 = <&uart2m1_gpios>;
		BT,wake_gpio = <&gpio1 0x0000000c 0x00000000>;
		status = "okay";
	};

	wireless-wlan {
		compatible = "wlan-platdata";
		rockchip,grf = <&grf>;
		wifi_chip_type = "AIC8800";
		pinctrl-names = "default";
		WIFI,host_wake_irq = <&gpio1 0x00000007 0x00000000>;
		status = "okay";
	};

	/* ==================== Reserved Memory ==================== */

	reserved-memory {
		#address-cells = <0x00000002>;
		#size-cells = <0x00000002>;
		ranges;

		cma {
			compatible = "shared-dma-pool";
			reusable;
			size = <0x00000000 0x00800000>;
			linux,cma-default;
		};

		drm_logo: drm-logo@0 {
			compatible = "rockchip,drm-logo";
			reg = <0x00000000 0x00000000 0x00000000 0x00000000>;
		};

		drm_cubic_lut: drm-cubic-lut@0 {
			compatible = "rockchip,drm-cubic-lut";
			reg = <0x00000000 0x00000000 0x00000000 0x00000000>;
		};

		ramoops@110000 {
			compatible = "ramoops";
			reg = <0x00000000 0x00110000 0x00000000 0x000f0000>;
			boot-log-size = <0x00008000>;
			boot-log-count = <0x00000001>;
			console-size = <0x00080000>;
			pmsg-size = <0x00010000>;
			ftrace-size = <0x00000000>;
			record-size = <0x00014000>;
		};
	};

	chosen {
		bootargs = "earlycon=uart8250,mmio32,0xffa00000 console=ttyFIQ0 driver_async_probe=dwmmc_rockchip,rockchip-drm drm_kms_helper.fbdev_emulation=0";
	};

	fiq-debugger {
		compatible = "rockchip,fiq-debugger";
		rockchip,serial-id = <0x00000002>;
		rockchip,wake-irq = <0x00000000>;
		rockchip,irq-mode-enable = <0x00000001>;
		rockchip,baudrate = <0x0016e360>;
		interrupts = <0x00000000 0x000000ba 0x00000004>;
		pinctrl-names = "default";
		pinctrl-0 = <&uart2m1_xfer>;
		status = "okay";
	};

	/* ==================== Pinctrl ==================== */

	gpu_opp_table: gpu-opp-table {
		compatible = "operating-points-v2";
		opp-300000000 {
			opp-hz = /bits/ 64 <300000000>;
			opp-microvolt = <875000>;
		};
		opp-500000000 {
			opp-hz = /bits/ 64 <500000000>;
			opp-microvolt = <950000>;
		};
		opp-700000000 {
			opp-hz = /bits/ 64 <700000000>;
			opp-microvolt = <1000000>;
		};
		opp-800000000 {
			opp-hz = /bits/ 64 <800000000>;
			opp-microvolt = <1050000>;
		};
	};

	pinctrl: pinctrl {
		compatible = "rockchip,rk3528-pinctrl";
		rockchip,grf = <&ioc_grf>;
		#address-cells = <0x00000002>;
		#size-cells = <0x00000002>;
		ranges;

		gpio0: gpio@ff610000 {
			compatible = "rockchip,gpio-bank";
			reg = <0x00000000 0xff610000 0x00000000 0x00000200>;
			interrupts = <0x00000000 0x00000047 0x00000004>;
			clocks = <&cru 0x000001fd>, <&cru 0x000001fe>;
			gpio-controller;
			#gpio-cells = <0x00000002>;
			gpio-ranges = <&pinctrl 0x00000000 0x00000000 0x00000020>;
			interrupt-controller;
			#interrupt-cells = <0x00000002>;
		};

		gpio1: gpio@ffaf0000 {
			compatible = "rockchip,gpio-bank";
			reg = <0x00000000 0xffaf0000 0x00000000 0x00000200>;
			interrupts = <0x00000000 0x00000049 0x00000004>;
			clocks = <&cru 0x000001fc>, <&cru 0x000000a9>;
			gpio-controller;
			#gpio-cells = <0x00000002>;
			gpio-ranges = <&pinctrl 0x00000000 0x00000020 0x00000020>;
			interrupt-controller;
			#interrupt-cells = <0x00000002>;
		};

		gpio2: gpio@ffb00000 {
			compatible = "rockchip,gpio-bank";
			reg = <0x00000000 0xffb00000 0x00000000 0x00000200>;
			interrupts = <0x00000000 0x0000004b 0x00000004>;
			clocks = <&cru 0x00000194>, <&cru 0x00000195>;
			gpio-controller;
			#gpio-cells = <0x00000002>;
			gpio-ranges = <&pinctrl 0x00000000 0x00000040 0x00000020>;
			interrupt-controller;
			#interrupt-cells = <0x00000002>;
		};

		gpio3: gpio@ffb10000 {
			compatible = "rockchip,gpio-bank";
			reg = <0x00000000 0xffb10000 0x00000000 0x00000200>;
			interrupts = <0x00000000 0x0000004c 0x00000004>;
			clocks = <&cru 0x000000ba>, <&cru 0x000000bb>;
			gpio-controller;
			#gpio-cells = <0x00000002>;
			gpio-ranges = <&pinctrl 0x00000000 0x00000060 0x00000020>;
			interrupt-controller;
			#interrupt-cells = <0x00000002>;
		};

		gpio4: gpio@ffb20000 {
			compatible = "rockchip,gpio-bank";
			reg = <0x00000000 0xffb20000 0x00000000 0x00000200>;
			interrupts = <0x00000000 0x0000004e 0x00000004>;
			clocks = <&cru 0x0000012c>, <&cru 0x0000012d>;
			gpio-controller;
			#gpio-cells = <0x00000002>;
			gpio-ranges = <&pinctrl 0x00000000 0x00000080 0x00000020>;
			interrupt-controller;
			#interrupt-cells = <0x00000002>;
		};

		/* Pull configs */
		pcfg_pull_up:   pcfg-pull-up   { bias-pull-up; };
		pcfg_pull_down: pcfg-pull-down { bias-pull-down; };
		pcfg_pull_none: pcfg-pull-none { bias-disable; };
		pcfg_pull_none_drv_level_2: pcfg-pull-none-drv-level-2 { bias-disable; drive-strength = <0x00000002>; };

		/* HDMI */
		hdmi {
			hdmi_pins: hdmi-pins {
				rockchip,pins =
					<0x00000000 0x00000000 0x00000001 &pcfg_pull_none>,
					<0x00000000 0x00000004 0x00000001 &pcfg_pull_none>,
					<0x00000000 0x00000005 0x00000001 &pcfg_pull_none>;
			};
		};

		/* fephy (integrated eth PHY) */
		fephy {
			fephym0_led_link: fephym0-led_link {
				rockchip,pins = <0x00000004 0x00000010 0x00000002 &pcfg_pull_none>;
			};
			fephym0_led_spd: fephym0-led_spd {
				rockchip,pins = <0x00000004 0x0000000f 0x00000002 &pcfg_pull_none>;
			};
		};

		/* UART2 (BT/debug) */
		uart2 {
			uart2m1_xfer: uart2m1-xfer {
				rockchip,pins =
					<0x00000001 0x00000008 0x00000001 &pcfg_pull_up>,
					<0x00000001 0x00000009 0x00000001 &pcfg_pull_up>;
			};
			uart2m1_gpios: uart2m1-gpios {
				rockchip,pins = <0x00000001 0x0000000a 0x00000000 &pcfg_pull_none>;
			};
		};

		/* BT wake */
		wireless-bluetooth {
			bt_wake_gpio: bt-wake-gpio {
				rockchip,pins = <0x00000001 0x0000000c 0x00000000 &pcfg_pull_none>;
			};
		};

		/* WiFi */
		wireless-wlan {
			wifi_enable_h: wifi-enable-h {
				rockchip,pins = <0x00000001 0x00000006 0x00000000 &pcfg_pull_none>;
			};
			wifi_host_wake_irq: wifi-host-wake-irq {
				rockchip,pins = <0x00000001 0x00000007 0x00000000 &pcfg_pull_down>;
			};
		};

		/* WiFi 32k clock */
		clk {
			wifi_32k: wifi-32k {
				rockchip,pins = <0x00000001 0x00000013 0x00000001 &pcfg_pull_none>;
			};
		};

		/* SDIO */
		sdio0 {
			sdio0_bus4: sdio0-bus4 {
				rockchip,pins =
					<0x00000001 0x00000000 0x00000001 &pcfg_pull_up>,
					<0x00000001 0x00000001 0x00000001 &pcfg_pull_up>,
					<0x00000001 0x00000002 0x00000001 &pcfg_pull_up>,
					<0x00000001 0x00000003 0x00000001 &pcfg_pull_up>;
			};
			sdio0_clk: sdio0-clk {
				rockchip,pins = <0x00000001 0x00000005 0x00000001 &pcfg_pull_none>;
			};
			sdio0_cmd: sdio0-cmd {
				rockchip,pins = <0x00000001 0x00000004 0x00000001 &pcfg_pull_up>;
			};
		};

		/* SD card */
		sdmmc {
			sdmmc_bus4: sdmmc-bus4 {
				rockchip,pins =
					<0x00000002 0x00000000 0x00000001 &pcfg_pull_up>,
					<0x00000002 0x00000001 0x00000001 &pcfg_pull_up>,
					<0x00000002 0x00000002 0x00000001 &pcfg_pull_up>,
					<0x00000002 0x00000003 0x00000001 &pcfg_pull_up>;
			};
			sdmmc_clk: sdmmc-clk {
				rockchip,pins = <0x00000002 0x00000005 0x00000001 &pcfg_pull_none>;
			};
			sdmmc_cmd: sdmmc-cmd {
				rockchip,pins = <0x00000002 0x00000004 0x00000001 &pcfg_pull_up>;
			};
			sdmmc_det: sdmmc-det {
				rockchip,pins = <0x00000002 0x00000006 0x00000001 &pcfg_pull_up>;
			};
		};

		/* USB VBUS */
		usb {
			vcc5v0_host_en: vcc5v0-host-en {
				rockchip,pins = <0x00000004 0x0000000d 0x00000000 &pcfg_pull_none>;
			};
			vcc5v0_otg_en: vcc5v0-otg-en {
				rockchip,pins = <0x00000004 0x00000011 0x00000000 &pcfg_pull_none>;
			};
		};

		/* PWM */
		pwm2 {
			pwm2m0_pins: pwm2m0-pins {
				rockchip,pins = <0x00000004 0x00000015 0x00000001 &pcfg_pull_none>;
			};
		};

		pwm3 {
			pwm3m0_pins: pwm3m0-pins {
				rockchip,pins = <0x00000004 0x00000016 0x00000001 &pcfg_pull_none>;
			};
		};

		/* I2C6 */
		i2c6 {
			i2c6m0_xfer: i2c6m0-xfer {
				rockchip,pins =
					<0x00000003 0x0000000a 0x00000005 &pcfg_pull_up>,
					<0x00000003 0x0000000b 0x00000005 &pcfg_pull_up>;
			};
		};

		/* RGMII (gmac1 - disabled) */
		rgmii {
			rgmii_miim: rgmii-miim {
				rockchip,pins =
					<0x00000003 0x0000000e 0x00000002 &pcfg_pull_none>,
					<0x00000003 0x0000000f 0x00000002 &pcfg_pull_none>;
			};
			rgmii_tx_bus2: rgmii-tx_bus2 {
				rockchip,pins =
					<0x00000003 0x00000001 0x00000002 &pcfg_pull_none>,
					<0x00000003 0x00000000 0x00000002 &pcfg_pull_none>,
					<0x00000003 0x00000010 0x00000002 &pcfg_pull_none>;
			};
			rgmii_rx_bus2: rgmii-rx_bus2 {
				rockchip,pins =
					<0x00000003 0x00000003 0x00000002 &pcfg_pull_none>,
					<0x00000003 0x00000002 0x00000002 &pcfg_pull_none>,
					<0x00000003 0x00000012 0x00000002 &pcfg_pull_none>;
			};
			rgmii_rgmii_clk: rgmii-rgmii_clk {
				rockchip,pins =
					<0x00000003 0x00000005 0x00000002 &pcfg_pull_none>,
					<0x00000003 0x00000004 0x00000002 &pcfg_pull_none>;
			};
			rgmii_bus: rgmii-bus {
				rockchip,pins =
					<0x00000003 0x00000007 0x00000002 &pcfg_pull_none>,
					<0x00000003 0x00000006 0x00000002 &pcfg_pull_none>,
					<0x00000003 0x00000009 0x00000002 &pcfg_pull_none>,
					<0x00000003 0x00000008 0x00000002 &pcfg_pull_none>;
			};
		};

		/* Keys */
		rockchip-key {
			power_key: power-key {
				rockchip,pins = <0x00000001 0x00000012 0x00000000 &pcfg_pull_up>;
			};
		};

		/* LEDs */
		leds {
			led_power_pin: led-power-pin {
				rockchip,pins = <0x00000004 0x0000000b 0x00000000 &pcfg_pull_none>;
			};
		};

		/* GPU */
		gpu {
			gpu_pins: gpu-pins {
				rockchip,pins = <0x00000004 0x00000013 0x00000003 &pcfg_pull_none>;
			};
		};
	};

	/* GPU pwm regulator placeholder - uses pwm0 based on DTS */
	pwm_vddgpu: pwm@ffa90000 {
		compatible = "rockchip,rk3528-pwm", "rockchip,rk3328-pwm";
		reg = <0x00000000 0xffa90000 0x00000000 0x00000010>;
		interrupts = <0x00000000 0x00000035 0x00000004>;
		#pwm-cells = <0x00000003>;
		clocks = <&cru 0x0000007f>, <&cru 0x0000007e>;
		clock-names = "pwm", "pclk";
		status = "okay";
	};
};

/* append gpu_opp_table stub - referenced by gpu node */
